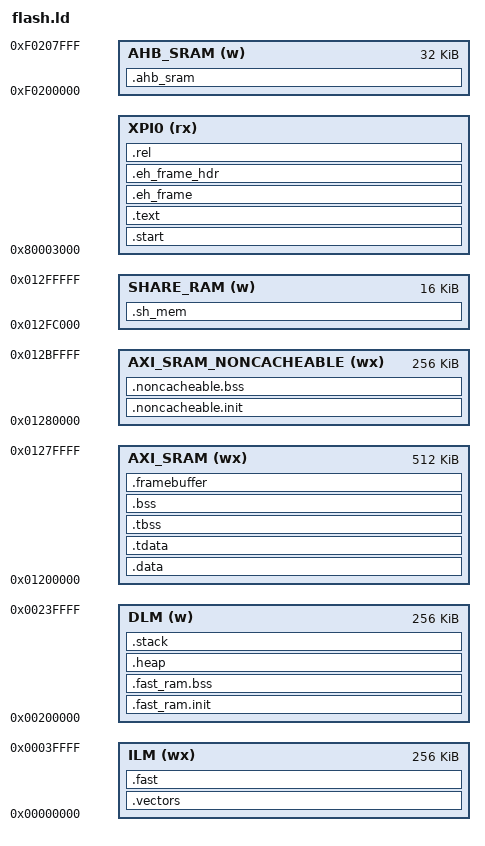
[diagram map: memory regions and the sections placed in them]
/*
 * Copyright (c) 2022-2023 HPMicro
 * SPDX-License-Identifier: BSD-3-Clause
 */

ENTRY(_start)

STACK_SIZE = _stack_size;
HEAP_SIZE = _heap_size;

MEMORY
{
    XPI0 (rx) : ORIGIN = 0x80003000, LENGTH = _flash_size - 0x3000
    ILM (wx) : ORIGIN = 0x00000000, LENGTH = 256K
    DLM (w) : ORIGIN = 0x00200000, LENGTH = 256K
    AXI_SRAM (wx) : ORIGIN = 0x01200000, LENGTH = 512K
    AXI_SRAM_NONCACHEABLE (wx) : ORIGIN = 0x01280000, LENGTH = 256K
    SHARE_RAM (w) : ORIGIN = 0x012FC000, LENGTH = 16K
    AHB_SRAM (w) : ORIGIN = 0xF0200000, LENGTH = 32k
}

SECTIONS
{
    .start : {
        . = ALIGN(8);
        KEEP(*(.start))
    } > XPI0

    __vector_load_addr__ = ADDR(.start) + SIZEOF(.start);
    .vectors ORIGIN(ILM) : AT(__vector_load_addr__) {
        . = ALIGN(8);
        __vector_ram_start__ = .;
        KEEP(*(.vector_table))
        KEEP(*(.isr_vector))
        KEEP(*(.vector_s_table))
        KEEP(*(.isr_s_vector))
        . = ALIGN(8);
        __vector_ram_end__ = .;
    } > ILM

    .text (__vector_load_addr__ + SIZEOF(.vectors)) : {
        . = ALIGN(8);
        *(.text)
        *(.text*)
        *(.rodata)
        *(.rodata*)
        *(.srodata)
        *(.srodata*)

        *(.hash)
        *(.dyn*)
        *(.gnu*)
        *(.pl*)

        KEEP (*(.init))
        KEEP (*(.fini))

        /* section information for usbh class */
        . = ALIGN(8);
        __usbh_class_info_start__ = .;
        KEEP(*(.usbh_class_info))
        __usbh_class_info_end__ = .;

        /* RT-Thread related sections - Start */
        /* section information for finsh shell */
        . = ALIGN(4);
        __fsymtab_start = .;
        KEEP(*(FSymTab))
        __fsymtab_end = .;
        . = ALIGN(4);
        __vsymtab_start = .;
        KEEP(*(VSymTab))
        __vsymtab_end = .;
        . = ALIGN(4);

        . = ALIGN(4);
        __rt_init_start = .;
        KEEP(*(SORT(.rti_fn*)))
        __rt_init_end = .;
        . = ALIGN(4);

        /* section information for modules */
        . = ALIGN(4);
        __rtmsymtab_start = .;
        KEEP(*(RTMSymTab))
        __rtmsymtab_end = .;

        /* RT-Thread related sections - end */
        . = ALIGN(8);
    } > XPI0

    .eh_frame :
    {
        __eh_frame_start = .;
        KEEP(*(.eh_frame))
        __eh_frame_end = .;
    }  > XPI0

    .eh_frame_hdr :
    {
        KEEP(*(.eh_frame_hdr))
    }  > XPI0
    __eh_frame_hdr_start = SIZEOF(.eh_frame_hdr) > 0 ? ADDR(.eh_frame_hdr) : 0;
    __eh_frame_hdr_end = SIZEOF(.eh_frame_hdr) > 0 ? . : 0;


    .rel : {
        KEEP(*(.rel*))
    } > XPI0

    PROVIDE (__etext = .);
    PROVIDE (_etext = .);
    PROVIDE (etext = .);

    __data_load_addr__ = etext;
    .data : AT(__data_load_addr__) {
        . = ALIGN(8);
        __data_start__ = .;
        __global_pointer$ = . + 0x800;
        *(.data)
        *(.data*)
        *(.sdata)
        *(.sdata*)

        KEEP(*(.jcr))
        KEEP(*(.dynamic))
        KEEP(*(.got*))
        KEEP(*(.got))
        KEEP(*(.gcc_except_table))
        KEEP(*(.gcc_except_table.*))

        . = ALIGN(8);
        PROVIDE(__preinit_array_start = .);
        KEEP(*(.preinit_array))
        PROVIDE(__preinit_array_end = .);

        . = ALIGN(8);
        PROVIDE(__init_array_start = .);
        KEEP(*(SORT_BY_INIT_PRIORITY(.init_array.*)))
        KEEP(*(.init_array))
        PROVIDE(__init_array_end = .);

        . = ALIGN(8);
        PROVIDE(__finit_array_start = .);
        KEEP(*(SORT_BY_INIT_PRIORITY(.finit_array.*)))
        KEEP(*(.finit_array))
        PROVIDE(__finit_array_end = .);

        . = ALIGN(8);
        KEEP(*crtbegin*.o(.ctors))
        KEEP(*(EXCLUDE_FILE (*crtend*.o) .ctors))
        KEEP(*(SORT(.ctors.*)))
        KEEP(*(.ctors))

        . = ALIGN(8);
        KEEP(*crtbegin*.o(.dtors))
        KEEP(*(EXCLUDE_FILE (*crtend*.o) .dtors))
        KEEP(*(SORT(.dtors.*)))
        KEEP(*(.dtors))
        . = ALIGN(8);
        __data_end__ = .;
        PROVIDE (__edata = .);
        PROVIDE (_edata = .);
        PROVIDE (edata = .);
    } > AXI_SRAM

    __fast_load_addr__ = etext + SIZEOF(.data);
    .fast : AT(__fast_load_addr__) {
        . = ALIGN(8);
        PROVIDE(__ramfunc_start__ = .);
        *(.fast)
        *(.fast.*)
        . = ALIGN(8);
        PROVIDE(__ramfunc_end__ = .);
    } > ILM

    __tdata_load_addr__ = etext + SIZEOF(.data) + SIZEOF(.fast);
    .tdata : AT(__tdata_load_addr__) {
        . = ALIGN(8);
        PROVIDE(__tdata_start__ = .);
        *(.tdata)
        *(.tdata.*)
        *(.gnu.linkonce.td.*)
        . = ALIGN(8);
        PROVIDE(__tdata_end__ = .);
    } > AXI_SRAM

    .tbss (NOLOAD) : {
        . = ALIGN(8);
        PROVIDE(__tbss_start__ = .);
        __thread_pointer$ = .;
        *(.tbss)
        *(.tbss.*)
        *(.gnu.linkonce.tb.*)
        *(.tcommon)
        . = ALIGN(8);
        PROVIDE(__tbss_end__ = .);
    } > AXI_SRAM

    __noncacheable_init_load_addr__ = etext + SIZEOF(.data) + SIZEOF(.fast) + SIZEOF(.tdata);
    .noncacheable.init : AT(__noncacheable_init_load_addr__) {
        . = ALIGN(8);
        __noncacheable_init_start__ = .;
        KEEP(*(.noncacheable.init))
        __noncacheable_init_end__ = .;
        . = ALIGN(8);
    } > AXI_SRAM_NONCACHEABLE

    __fast_ram_init_load_addr__ = etext + SIZEOF(.data) + SIZEOF(.fast) + SIZEOF(.tdata) + SIZEOF(.noncacheable.init);
    .fast_ram.init : AT(__fast_ram_init_load_addr__) {
        . = ALIGN(8);
        __fast_ram_init_start__ = .;
        KEEP(*(.fast_ram.init))
        __fast_ram_init_end__ = .;
        . = ALIGN(8);
    } > DLM

    .bss (NOLOAD) : {
        . = ALIGN(8);
        __bss_start__ = .;
        *(.bss)
        *(.bss*)
        *(.sbss*)
        *(.scommon)
        *(.scommon*)
        *(.dynsbss*)
        *(COMMON)
        . = ALIGN(8);
        _end = .;
        __bss_end__ = .;
    } > AXI_SRAM

    .framebuffer (NOLOAD) : {
        . = ALIGN(8);
        KEEP(*(.framebuffer))
        . = ALIGN(8);
    } > AXI_SRAM

    .noncacheable.bss (NOLOAD) : {
        . = ALIGN(8);
        KEEP(*(.noncacheable))
        __noncacheable_bss_start__ = .;
        KEEP(*(.noncacheable.bss))
        __noncacheable_bss_end__ = .;
        . = ALIGN(8);
    } > AXI_SRAM_NONCACHEABLE

    .sh_mem (NOLOAD) : {
        KEEP(*(.sh_mem))
    } > SHARE_RAM

    .ahb_sram (NOLOAD) : {
        KEEP(*(.ahb_sram))
    } > AHB_SRAM

    .fast_ram.bss (NOLOAD) : {
        . = ALIGN(8);
        KEEP(*(.fast_ram))
        __fast_ram_bss_start__ = .;
        KEEP(*(.fast_ram.bss))
        __fast_ram_bss_end__ = .;
        . = ALIGN(8);
    } > DLM

    .heap (NOLOAD) : {
        . = ALIGN(8);
        __heap_start__ = .;
        . += HEAP_SIZE;
        __heap_end__ = .;
    } > DLM

    .stack (NOLOAD) : {
        . = ALIGN(16);
        __stack_base__ = .;
        . += STACK_SIZE;
        . = ALIGN(16);
        PROVIDE (_stack = .);
        PROVIDE (_stack_safe = .);
    } > DLM

    __noncacheable_start__ = ORIGIN(AXI_SRAM_NONCACHEABLE);
    __noncacheable_end__ = ORIGIN(AXI_SRAM_NONCACHEABLE) + LENGTH(AXI_SRAM_NONCACHEABLE);
    __share_mem_start__ = ORIGIN(SHARE_RAM);
    __share_mem_end__ = ORIGIN(SHARE_RAM) + LENGTH(SHARE_RAM);

    __fw_size__ = SIZEOF(.start) + SIZEOF(.vectors) + SIZEOF(.rel) + SIZEOF(.text) + SIZEOF(.data) + SIZEOF(.fast) + SIZEOF(.tdata) + SIZEOF(.noncacheable.init) + SIZEOF(.fast_ram.init);
    __last_addr__ = __fast_ram_init_load_addr__ + SIZEOF(.fast_ram.init);
    ASSERT(((__fw_size__ <= LENGTH(XPI0)) && (__last_addr__ <= (ORIGIN(XPI0) + LENGTH(XPI0)))), "******  FAILED! XPI0 has not enough space!  ******")
}
